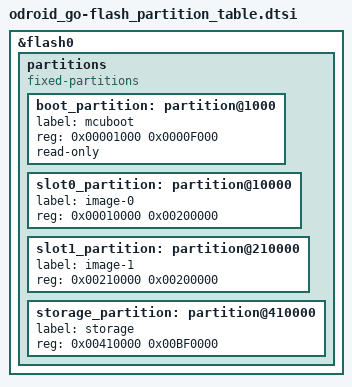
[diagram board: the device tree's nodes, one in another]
/*
 * Copyright (c) 2024 Yannis Damigos
 *
 * SPDX-License-Identifier: Apache-2.0
 */

&flash0 {
	status = "okay";
	partitions {
		compatible = "fixed-partitions";
		#address-cells = <1>;
		#size-cells = <1>;

		/* Reserve 60kB for the bootloader */
		boot_partition: partition@1000 {
			label = "mcuboot";
			reg = <0x00001000 0x0000F000>;
			read-only;
		};

		/* Reserve 2048kB for the application in slot 0 */
		slot0_partition: partition@10000 {
			label = "image-0";
			reg = <0x00010000 0x00200000>;
		};

		/* Reserve 2048kB for the application in slot 1 */
		slot1_partition: partition@210000 {
			label = "image-1";
			reg = <0x00210000 0x00200000>;
		};

		/* Reserve the remaining 12224kB for the storage partition */
		storage_partition: partition@410000 {
			label = "storage";
			reg = <0x00410000 0x00BF0000>;
		};
	};
};
